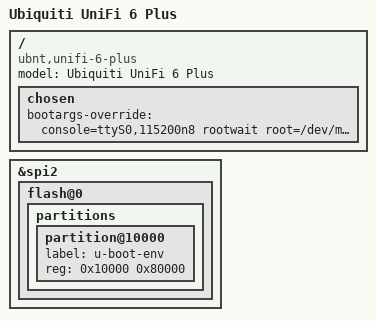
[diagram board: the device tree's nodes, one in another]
// SPDX-License-Identifier: GPL-2.0-or-later OR MIT

/dts-v1/;

#include "mt7981a-ubnt-unifi-6-plus.dtsi"

/ {
	model = "Ubiquiti UniFi 6 Plus";
	compatible = "ubnt,unifi-6-plus", "mediatek,mt7981";

	chosen {
		bootargs-override = "console=ttyS0,115200n8 rootwait root=/dev/mmcblk0p7";
	};
};

&spi2 {
	flash@0 {
		partitions {
			partition@10000 {
				label = "u-boot-env";
				reg = <0x10000 0x80000>;
			};
		};
	};
};
